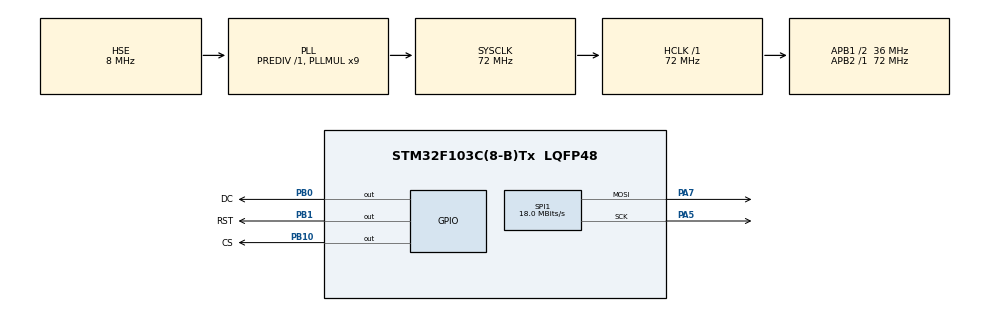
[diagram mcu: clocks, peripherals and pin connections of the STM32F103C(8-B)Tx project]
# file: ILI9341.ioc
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Dma.Request0=SPI1_TX
Dma.SPI1_TX.0.Direction=DMA_MEMORY_TO_PERIPH
Dma.SPI1_TX.0.Instance=DMA1_Channel3
Dma.SPI1_TX.0.MemDataAlignment=DMA_MDATAALIGN_BYTE
Dma.SPI1_TX.0.MemInc=DMA_MINC_ENABLE
Dma.SPI1_TX.0.Mode=DMA_NORMAL
Dma.SPI1_TX.0.PeriphDataAlignment=DMA_PDATAALIGN_BYTE
Dma.SPI1_TX.0.PeriphInc=DMA_PINC_DISABLE
Dma.SPI1_TX.0.Priority=DMA_PRIORITY_LOW
Mcu.Family=STM32F1
Mcu.Name=STM32F103C(8-B)Tx
Mcu.Package=LQFP48
NVIC.DMA1_Channel3_IRQn=true\:0\:0\:false\:false\:true\:false\:true\:true
NVIC.PriorityGroup=NVIC_PRIORITYGROUP_4
PA13.Mode=Serial_Wire
PA13.Signal=SYS_JTMS-SWDIO
PA14.Mode=Serial_Wire
PA14.Signal=SYS_JTCK-SWCLK
PA5.Mode=TX_Only_Simplex_Unidirect_Master
PA5.Signal=SPI1_SCK
PA7.Mode=TX_Only_Simplex_Unidirect_Master
PA7.Signal=SPI1_MOSI
PB0.GPIO_Label=DC
PB0.Signal=GPIO_Output
PB1.GPIO_Label=RST
PB1.Signal=GPIO_Output
PB10.GPIO_Label=CS
PB10.Signal=GPIO_Output
PD0-OSC_IN.Mode=HSE-External-Oscillator
PD0-OSC_IN.Signal=RCC_OSC_IN
PD1-OSC_OUT.Mode=HSE-External-Oscillator
PD1-OSC_OUT.Signal=RCC_OSC_OUT
ProjectManager.HeapSize=0x200
ProjectManager.StackSize=0x400
ProjectManager.TargetToolchain=STM32CubeIDE
RCC.AHBFreq_Value=72000000
RCC.APB1CLKDivider=RCC_HCLK_DIV2
RCC.APB1Freq_Value=36000000
RCC.APB1TimFreq_Value=72000000
RCC.APB2Freq_Value=72000000
RCC.APB2TimFreq_Value=72000000
RCC.HCLKFreq_Value=72000000
RCC.PLLMUL=RCC_PLL_MUL9
RCC.PLLSourceVirtual=RCC_PLLSOURCE_HSE
RCC.SYSCLKFreq_VALUE=72000000
RCC.SYSCLKSource=RCC_SYSCLKSOURCE_PLLCLK
RCC.USBFreq_Value=72000000
SPI1.BaudRatePrescaler=SPI_BAUDRATEPRESCALER_4
SPI1.CalculateBaudRate=18.0 MBits/s
SPI1.Direction=SPI_DIRECTION_2LINES
SPI1.Mode=SPI_MODE_MASTER
SPI1.VirtualType=VM_MASTER
board=custom

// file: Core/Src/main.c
/* USER CODE BEGIN Header */
/**
  ******************************************************************************
  * @file           : main.c
  * @brief          : Main program body
  ******************************************************************************
  * @attention
  *
  * Copyright (c) 2023 STMicroelectronics.
  * All rights reserved.
  *
  * This software is licensed under terms that can be found in the LICENSE file
  * in the root directory of this software component.
  * If no LICENSE file comes with this software, it is provided AS-IS.
  *
  ******************************************************************************
  */
/* USER CODE END Header */
#include "main.h"
#include "dma.h"
#include "spi.h"
#include "gpio.h"

/* USER CODE BEGIN Includes */
#include <stdio.h>
#include "ILI9341_STM32_Driver.h"
#include "ILI9341_GFX.h"
/* USER CODE END Includes */

/* USER CODE BEGIN PV */
extern SPI_HandleTypeDef hspi1;
/* USER CODE END PV */

void SystemClock_Config(void);

/* USER CODE BEGIN 0 */
  static connection_info_t ci = {
    {RST_GPIO_Port, RST_Pin},
    {DC_GPIO_Port, DC_Pin},
    {CS_GPIO_Port, CS_Pin},
    &hspi1
  };

/* USER CODE END 0 */

int main(void)
{

  /* MCU Configuration--------------------------------------------------------*/

  /* Reset of all peripherals, Initializes the Flash interface and the Systick. */
  HAL_Init();

  /* Configure the system clock */
  SystemClock_Config();

  /* Initialize all configured peripherals */
  MX_GPIO_Init();
  MX_DMA_Init();
  MX_SPI1_Init();
  /* USER CODE BEGIN 2 */
  ILI9341_Init_Ex(&ci);
  /* USER CODE END 2 */

  /* Infinite loop */
  /* USER CODE BEGIN WHILE */
  while (1)
  {

  // Simple Text writing (Text, Font, X, Y, Color, BackColor)
  // Available Fonts are FONT1, FONT2, FONT3 and FONT4
  ILI9341_FillScreen(WHITE);
  ILI9341_SetRotation(SCREEN_HORIZONTAL_1);
  ILI9341_DrawText("HELLO WORLD", FONT4, 90, 110, BLACK, WHITE);
  HAL_Delay(1000);

  //Writing numbers
  ILI9341_FillScreen(WHITE);
  static char BufferText[30];
  for(uint8_t i = 0; i <= 5; i++)
  {
    sprintf(BufferText, "COUNT : %d", i);
    ILI9341_DrawText(BufferText, FONT3, 10, 10, BLACK, WHITE);
    ILI9341_DrawText(BufferText, FONT3, 10, 30, BLUE, WHITE);
    ILI9341_DrawText(BufferText, FONT3, 10, 50, RED, WHITE);
    ILI9341_DrawText(BufferText, FONT3, 10, 70, GREEN, WHITE);
    ILI9341_DrawText(BufferText, FONT3, 10, 90, YELLOW, WHITE);
    ILI9341_DrawText(BufferText, FONT3, 10, 110, PURPLE, WHITE);
    ILI9341_DrawText(BufferText, FONT3, 10, 130, ORANGE, WHITE);
    ILI9341_DrawText(BufferText, FONT3, 10, 150, MAROON, WHITE);
    ILI9341_DrawText(BufferText, FONT3, 10, 170, WHITE, BLACK);
    ILI9341_DrawText(BufferText, FONT3, 10, 190, BLUE, BLACK);
  }

  // Horizontal Line (X, Y, Length, Color)
  ILI9341_FillScreen(WHITE);
  ILI9341_DrawHLine(50, 120, 200, NAVY);
  HAL_Delay(1000);

  // Vertical Line (X, Y, Length, Color)
  ILI9341_FillScreen(WHITE);
  ILI9341_DrawVLine(160, 40, 150, DARKGREEN);
  HAL_Delay(1000);

  // Hollow Circle (Centre X, Centre Y, Radius, Color)
  ILI9341_FillScreen(WHITE);
  ILI9341_DrawHollowCircle(160, 120, 80, PINK);
  HAL_Delay(1000);

  // Filled Circle (Centre X, Centre Y, Radius, Color)
  ILI9341_FillScreen(WHITE);
  ILI9341_DrawFilledCircle(160, 120, 50, CYAN);
  HAL_Delay(1000);

  // Filled Rectangle (Start X, Start Y, Length X, Length Y)
  ILI9341_FillScreen(WHITE);
  ILI9341_DrawRectangle(50, 50, 220, 140, GREENYELLOW);
  HAL_Delay(1000);

  // Hollow Rectangle (Start X, Start Y, End X, End Y)
  ILI9341_FillScreen(WHITE);
  ILI9341_DrawHollowRectangleCoord(50, 50, 270, 190, DARKCYAN);
  HAL_Delay(1000);

  // Simple Pixel Only (X, Y, Color)
  ILI9341_FillScreen(WHITE);
  ILI9341_DrawPixel(100, 100, BLACK);
  HAL_Delay(1000);

    /* USER CODE END WHILE */

  }
}

void SystemClock_Config(void)
{
  RCC_OscInitTypeDef RCC_OscInitStruct = {0};
  RCC_ClkInitTypeDef RCC_ClkInitStruct = {0};

  /** Initializes the RCC Oscillators according to the specified parameters
  * in the RCC_OscInitTypeDef structure.
  */
  RCC_OscInitStruct.OscillatorType = RCC_OSCILLATORTYPE_HSE;
  RCC_OscInitStruct.HSEState = RCC_HSE_ON;
  RCC_OscInitStruct.HSEPredivValue = RCC_HSE_PREDIV_DIV1;
  RCC_OscInitStruct.HSIState = RCC_HSI_ON;
  RCC_OscInitStruct.PLL.PLLState = RCC_PLL_ON;
  RCC_OscInitStruct.PLL.PLLSource = RCC_PLLSOURCE_HSE;
  RCC_OscInitStruct.PLL.PLLMUL = RCC_PLL_MUL9;
  if (HAL_RCC_OscConfig(&RCC_OscInitStruct) != HAL_OK)
  {
    Error_Handler();
  }

  /** Initializes the CPU, AHB and APB buses clocks
  */
  RCC_ClkInitStruct.ClockType = RCC_CLOCKTYPE_HCLK|RCC_CLOCKTYPE_SYSCLK
                              |RCC_CLOCKTYPE_PCLK1|RCC_CLOCKTYPE_PCLK2;
  RCC_ClkInitStruct.SYSCLKSource = RCC_SYSCLKSOURCE_PLLCLK;
  RCC_ClkInitStruct.AHBCLKDivider = RCC_SYSCLK_DIV1;
  RCC_ClkInitStruct.APB1CLKDivider = RCC_HCLK_DIV2;
  RCC_ClkInitStruct.APB2CLKDivider = RCC_HCLK_DIV1;

  if (HAL_RCC_ClockConfig(&RCC_ClkInitStruct, FLASH_LATENCY_2) != HAL_OK)
  {
    Error_Handler();
  }
}

void Error_Handler(void)
{
  __disable_irq();
  while (1)
  {
  }
}
